# PIC32CX5112MTSH128 register map
Vendor: Microchip Technology; Series: PIC32CXMTSH; File version: 0
CPU: CM4 r0p1, selectable endian, MPU, FPU, 4 interrupt priority bits
Registers are 32-bit, read-write, reset 0x0 unless marked. A register's access mark holds for its fields unless they carry their own. Offsets are from the block's base; [hi:lo] are bit positions; {n}, {i} and the like mark numbered series.

## ICM — Integrity Check Monitor
Base 0x44010000; register names take the prefix ICM_
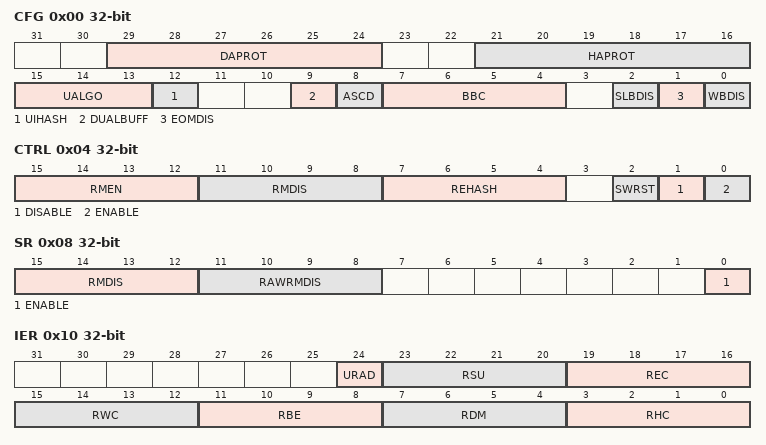
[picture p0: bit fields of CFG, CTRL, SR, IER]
0x00 CFG — Configuration Register
  [29:24] DAPROT — Region Descriptor Area Protection
  [21:16] HAPROT — Region Hash Area Protection
  [15:13] UALGO — User SHA Algorithm
    0=SHA1 (SHA1 algorithm processed); 1=SHA256 (SHA256 algorithm processed); 2=SHA384 (SHA384 algorithm processed); 3=SHA512 (SHA512 algorithm processed); 4=SHA224 (SHA224 algorithm processed)
  [12] UIHASH — User Initial Hash Value
  [9] DUALBUFF — Dual Input Buffer
  [8] ASCD — Automatic Switch To Compare Digest
  [7:4] BBC — Bus Burden Control
  [2] SLBDIS — Secondary List Branching Disable
  [1] EOMDIS — End of Monitoring Disable
  [0] WBDIS — Write-Back Disable
0x04 CTRL wo — Control Register
  [15:12] RMEN — Region Monitoring Enable
  [11:8] RMDIS — Region Monitoring Disable
  [7:4] REHASH — Recompute Internal Hash
  [2] SWRST — Software Reset
  [1] DISABLE — ICM Disable Register
  [0] ENABLE — ICM Enable
0x08 SR ro — Status Register
  [15:12] RMDIS — Region Monitoring Disabled Status
  [11:8] RAWRMDIS — Region Monitoring Disabled Raw Status
  [0] ENABLE — ICM Enable Register
0x10 IER wo — Interrupt Enable Register
  [24] URAD — Undefined Register Access Detection Interrupt Enable
  [23:20] RSU — Region Status Updated Interrupt Disable
  [19:16] REC — Region End bit Condition Detected Interrupt Enable
  [15:12] RWC — Region Wrap Condition detected Interrupt Enable
  [11:8] RBE — Region Bus Error Interrupt Enable
  [7:4] RDM — Region Digest Mismatch Interrupt Enable
  [3:0] RHC — Region Hash Completed Interrupt Enable
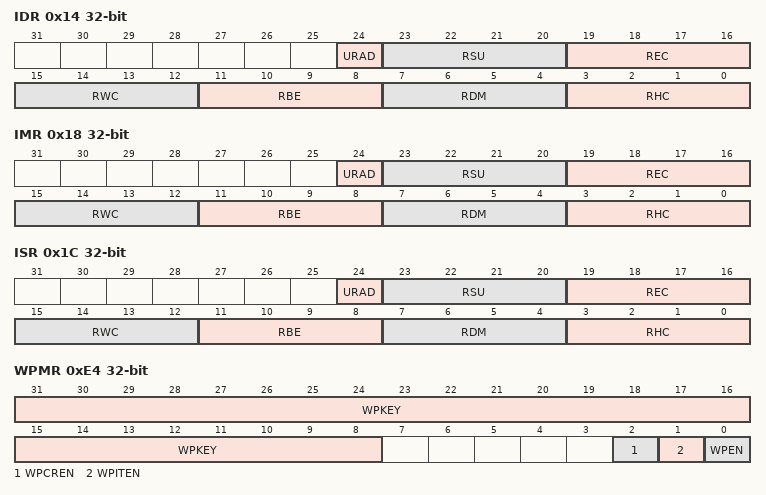
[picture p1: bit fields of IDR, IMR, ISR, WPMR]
0x14 IDR wo — Interrupt Disable Register
  [24] URAD — Undefined Register Access Detection Interrupt Disable
  [23:20] RSU — Region Status Updated Interrupt Disable
  [19:16] REC — Region End bit Condition detected Interrupt Disable
  [15:12] RWC — Region Wrap Condition Detected Interrupt Disable
  [11:8] RBE — Region Bus Error Interrupt Disable
  [7:4] RDM — Region Digest Mismatch Interrupt Disable
  [3:0] RHC — Region Hash Completed Interrupt Disable
0x18 IMR ro — Interrupt Mask Register
  [24] URAD — Undefined Register Access Detection Interrupt Mask
  [23:20] RSU — Region Status Updated Interrupt Mask
  [19:16] REC — Region End bit Condition Detected Interrupt Mask
  [15:12] RWC — Region Wrap Condition Detected Interrupt Mask
  [11:8] RBE — Region Bus Error Interrupt Mask
  [7:4] RDM — Region Digest Mismatch Interrupt Mask
  [3:0] RHC — Region Hash Completed Interrupt Mask
0x1C ISR ro — Interrupt Status Register
  [24] URAD — Undefined Register Access Detection Status
  [23:20] RSU — Region Status Updated Detected
  [19:16] REC — Region End Bit Condition Detected
  [15:12] RWC — Region Wrap Condition Detected
  [11:8] RBE — Region Bus Error
  [7:4] RDM — Region Digest Mismatch
  [3:0] RHC — Region Hash Completed
0x20 UASR ro — Undefined Access Status Register
  [2:0] URAT — Undefined Register Access Trace
    0=UNSPEC_STRUCT_MEMBER (Unspecified structure member set to one detected when the descriptor is loaded.); 1=ICM_CFG_MODIFIED (ICM_CFG modified during active monitoring.); 2=ICM_DSCR_MODIFIED (ICM_DSCR modified during active monitoring.); 3=ICM_HASH_MODIFIED (ICM_HASH modified during active monitoring); 4=READ_ACCESS (Write-only register read access)
0x30 DSCR — Region Descriptor Area Start Address Register
  [31:6] DASA — Descriptor Area Start Address
0x34 HASH — Region Hash Area Start Address Register
  [31:8] HASA — Hash Area Start Address
{0x38+4i} UIHVAL[{i}] (i=0..15) wo — User Initial Hash Value 0 Register
  [31:0] VAL — Initial Hash Value
0xE4 WPMR — Write Protection Mode Register
  [31:8] WPKEY — Write Protection Key
    0x49434D=PASSWD (Writing any other value in this field aborts the write operation of the WPEN, WPITEN and WPCREN bits. Always reads as 0)
  [2] WPCREN — Write Protection Control Enable
  [1] WPITEN — Write Protection Interrupt Enable
  [0] WPEN — Write Protection Enable
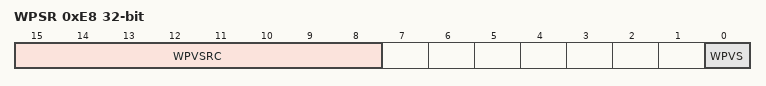
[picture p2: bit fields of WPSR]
0xE8 WPSR ro — Write Protection Status Register
  [15:8] WPVSRC — Write Protection Violation Source
  [0] WPVS — Write Protection Violation Status (Cleared on read)
